# CY8C5568AXI_060 register map
File version: 0.1
Registers are 8-bit, read-write, no defined reset value unless marked. A register's access mark holds for its fields unless they carry their own. Offsets are from the block's base; [hi:lo] are bit positions; 'fields as' and 'values as' point back to an identical list.

## Motor_1_PWM_9
Base 0x40006524
0x00 Motor_1_PWM_9_COMPARE_Reg_ — UDB.D0 - Assigned Compare Value
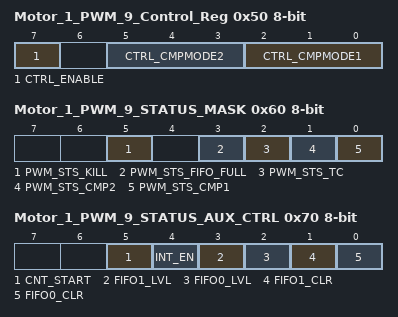
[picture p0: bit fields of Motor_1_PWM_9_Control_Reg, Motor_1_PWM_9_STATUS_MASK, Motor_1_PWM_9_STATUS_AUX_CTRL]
0x50 Motor_1_PWM_9_Control_Reg — UDB Control Register - Assigned Control Register Value
  [7] CTRL_ENABLE — Enable the PWM
  [5:3] CTRL_CMPMODE2 — Compare mode 2
  [2:0] CTRL_CMPMODE1 — Compare mode 1
0x60 Motor_1_PWM_9_STATUS_MASK — UDB Status bits Interrupt Mask Enable Register
  [5] PWM_STS_KILL ro — Enables the Interrupt on Kill
  [3] PWM_STS_FIFO_FULL ro — FIFO Full Status Mask
  [2] PWM_STS_TC ro — Enables the Interrupt on Terminal Count
  [1] PWM_STS_CMP2 ro — Enables the Interrupt on Compare 2
  [0] PWM_STS_CMP1 ro — Enables the Interrupt on Compare 1
0x70 Motor_1_PWM_9_STATUS_AUX_CTRL — UDB Auxilliary Control Register
  [5] CNT_START — FIFO0 clear
    0=E_CNT_START0 (Disable counter); 1=E_CNT_START1 (Enable counter)
  [4] INT_EN
    0=E_INT_EN0 (Interrupt disabled); 1=E_INT_EN1 (Interrupt enabled)
  [3] FIFO1_LVL — FIFO level
    0=E_FIFO_LVL_0 (FIFO LVL: input mode: FIFO not full; output mode: FIFO not empty); 1=E_FIFO_LVL_1 (FIFO LVL: input mode: FIFO at least 1/2 empty; output mode: FIFO at least 1/2 full)
  [2] FIFO0_LVL — FIFO level
    values as FIFO1_LVL
  [1] FIFO1_CLR — FIFO1 clear
    0=E_FIFO_CLR_0 (Normal FIFO operation); 1=E_FIFO_CLR_1 (Clear FIFO state)
  [0] FIFO0_CLR — FIFO0 clear
    values as FIFO1_CLR

## Motor_1_PWM_10
Base 0x40006426
Registers as Motor_1_PWM_9 (with Motor_1_PWM_9 read as Motor_1_PWM_10), without Motor_1_PWM_9_Control_Reg; these are added or differ:
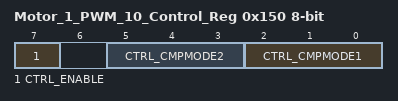
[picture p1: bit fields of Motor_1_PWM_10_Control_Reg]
0x150 Motor_1_PWM_10_Control_Reg — UDB Control Register - Assigned Control Register Value
  [7] CTRL_ENABLE — Enable the PWM
  [5:3] CTRL_CMPMODE2 — Compare mode 2
  [2:0] CTRL_CMPMODE1 — Compare mode 1

## Motor_1_PWM_11
Base 0x40006428
Registers as Motor_1_PWM_9 (with Motor_1_PWM_9 read as Motor_1_PWM_11), without Motor_1_PWM_9_COMPARE_Reg_, Motor_1_PWM_9_Control_Reg, Motor_1_PWM_9_STATUS_MASK; these are added or differ:
0x00 Motor_1_PWM_11__COMPARE1 — UDB.D0 - Assigned Compare1 Value
0x10 Motor_1_PWM_11__COMPARE2 — UDB.D1 - Assigned Compare2 Value
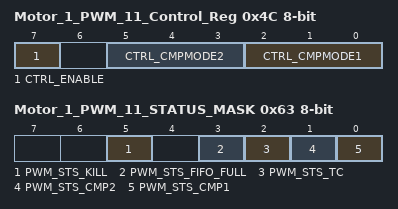
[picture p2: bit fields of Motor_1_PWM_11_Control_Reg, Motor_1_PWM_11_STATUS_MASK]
0x4C Motor_1_PWM_11_Control_Reg — UDB Control Register - Assigned Control Register Value
  [7] CTRL_ENABLE — Enable the PWM
  [5:3] CTRL_CMPMODE2 — Compare mode 2
  [2:0] CTRL_CMPMODE1 — Compare mode 1
0x63 Motor_1_PWM_11_STATUS_MASK — UDB Status bits Interrupt Mask Enable Register
  fields as Motor_1_PWM_9.Motor_1_PWM_9_STATUS_MASK

## Motor_1_PWM_15
Base 0x40006421
Registers as Motor_1_PWM_9 (with Motor_1_PWM_9 read as Motor_1_PWM_15).

## Motor_1_PWM_16
Base 0x40006423
Registers as Motor_1_PWM_9 (with Motor_1_PWM_9 read as Motor_1_PWM_16), without Motor_1_PWM_9_Control_Reg, Motor_1_PWM_9_STATUS_MASK; these are added or differ:
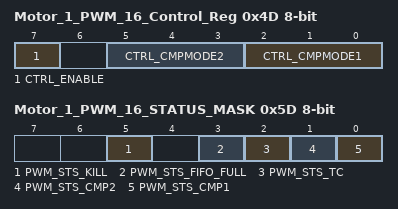
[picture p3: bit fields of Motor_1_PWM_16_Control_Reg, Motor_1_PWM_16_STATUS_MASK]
0x4D Motor_1_PWM_16_Control_Reg — UDB Control Register - Assigned Control Register Value
  [7] CTRL_ENABLE — Enable the PWM
  [5:3] CTRL_CMPMODE2 — Compare mode 2
  [2:0] CTRL_CMPMODE1 — Compare mode 1
0x5D Motor_1_PWM_16_STATUS_MASK — UDB Status bits Interrupt Mask Enable Register
  fields as Motor_1_PWM_9.Motor_1_PWM_9_STATUS_MASK

## Motor_1_PWM_12
Base 0x40006528
Registers as Motor_1_PWM_9 (with Motor_1_PWM_9 read as Motor_1_PWM_12), without Motor_1_PWM_9_COMPARE_Reg_; these are added or differ:
0x00 Motor_1_PWM_12__COMPARE1 — UDB.D0 - Assigned Compare1 Value
0x10 Motor_1_PWM_12__COMPARE2 — UDB.D1 - Assigned Compare2 Value

## Motor_1_PWM_13
Base 0x40006529
Registers as Motor_1_PWM_12 (with Motor_1_PWM_12 read as Motor_1_PWM_13).

## Motor_1_PWM_14
Base 0x40006429
Registers as Motor_1_PWM_12 (with Motor_1_PWM_12 read as Motor_1_PWM_14).

## Motor_1_PWM_2
Base 0x40006527
Registers as Motor_1_PWM_12 (with Motor_1_PWM_12 read as Motor_1_PWM_2).

## Motor_1_PWM_1
Base 0x40006425
Registers as Motor_1_PWM_9 (with Motor_1_PWM_9 read as Motor_1_PWM_1).

## Motor_1_PWM_5
Base 0x40006422
Registers as Motor_1_PWM_9 (with Motor_1_PWM_9 read as Motor_1_PWM_5).

## Motor_1_PWM_3
Base 0x4000652B
Registers as Motor_1_PWM_12 (with Motor_1_PWM_12 read as Motor_1_PWM_3).

## Motor_1_PWM_8
Base 0x40006424
Registers as Motor_1_PWM_9 (with Motor_1_PWM_9 read as Motor_1_PWM_8), without Motor_1_PWM_9_Control_Reg; these are added or differ:
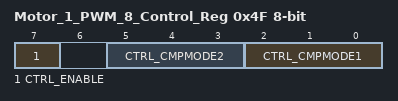
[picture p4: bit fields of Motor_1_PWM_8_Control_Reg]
0x4F Motor_1_PWM_8_Control_Reg — UDB Control Register - Assigned Control Register Value
  [7] CTRL_ENABLE — Enable the PWM
  [5:3] CTRL_CMPMODE2 — Compare mode 2
  [2:0] CTRL_CMPMODE1 — Compare mode 1

## Motor_1_PWM_7
Base 0x4000642B
Registers as Motor_1_PWM_12 (with Motor_1_PWM_12 read as Motor_1_PWM_7), without Motor_1_PWM_12_STATUS_MASK; these are added or differ:
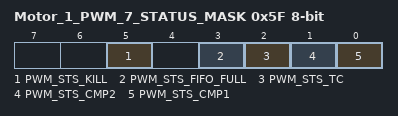
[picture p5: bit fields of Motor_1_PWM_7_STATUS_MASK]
0x5F Motor_1_PWM_7_STATUS_MASK — UDB Status bits Interrupt Mask Enable Register
  fields as Motor_1_PWM_9.Motor_1_PWM_9_STATUS_MASK

## Motor_1_PWM_6
Base 0x40006525
Registers as Motor_1_PWM_12 (with Motor_1_PWM_12 read as Motor_1_PWM_6).
